# CORE_LA register map
Vendor: Texas Instruments
Peripheral module from a debugger description file (folder omap36xx).
Registers are 32-bit, read-only, reset values left out (the file's numbers can be read two ways) unless marked. A register's access mark holds for its fields unless they carry their own. Offsets are as the file gives them; lines under a group give offsets from that group; [hi:lo] are bit positions; {n}, {i} and the like mark numbered series; 'fields as' and 'values as' point back to an identical list; <NAME> marks a mode.

## CORE_LA
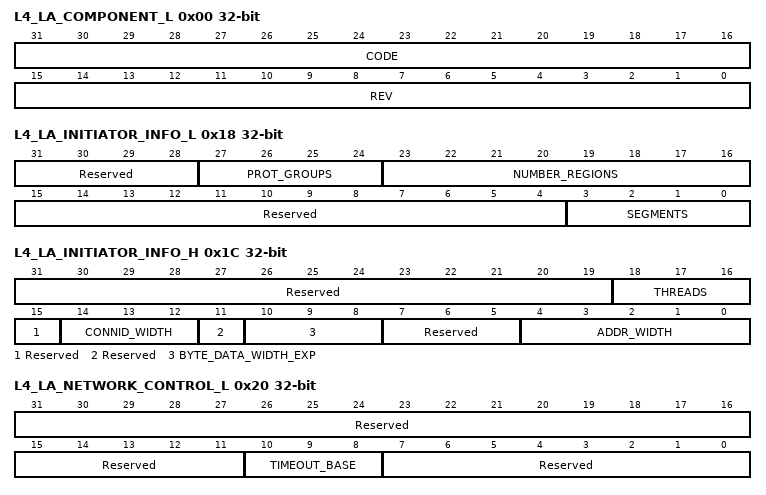
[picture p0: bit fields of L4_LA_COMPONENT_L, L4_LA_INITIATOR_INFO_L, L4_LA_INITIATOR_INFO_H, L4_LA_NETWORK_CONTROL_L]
0x00 L4_LA_COMPONENT_L — Contain a component code and revision, which are used to identify the hardware of the component.
  [31:16] CODE — Interconnect code.
  [15:0] REV — Component revision code.
0x04 L4_LA_COMPONENT_H — Contain a component code and revision, which are used to identify the hardware of the component.
  [31:0] Reserved — Read returns 0
0x10 L4_LA_NETWORK_L — Identify the interconnect
  [31:0] Reserved — Read returns 0
0x14 L4_LA_NETWORK_H — Identify the interconnect
  [31:0] ID — The ID field uniquely identifies this interconnect, and can serve as a chip ID.
0x18 L4_LA_INITIATOR_INFO_L — Contain initiator subsystem information.
  [31:28] Reserved — Read returns 0.
  [27:24] PROT_GROUPS — The number of protection groups. The PROT_GROUPS field contains read-only configuration information for the address mapping and protection structure of the initiator subsystem. If the PROT_GROUPS field is set to 0, there are no protection group registers.
  [23:16] NUMBER_REGIONS — The number of regions. The NUMBER_REGIONS field contains read-only configuration information for the region register of the initiator subsystem.
  [15:4] Reserved — Read returns 0.
  [3:0] SEGMENTS — The number of segments. The SEGMENT fields contains read-only configuration information for the segment register of the initiator subsystem.
0x1C L4_LA_INITIATOR_INFO_H — Contain initiator subsystem information.
  [31:19] Reserved — Read returns 0.
  [18:16] THREADS — The THREADS field specifies the number of initiator threads connected to the interconnect. The field contains read-only configuration information for the initiator subsystem.
  [15] Reserved — Read returns 0.
  [14:12] CONNID_WIDTH — The initiator subsystem connID width. The CONNID_WIDTH field contains read-only configuration information for the initiator subsystem.
  [11] Reserved — Read returns 0.
  [10:8] BYTE_DATA_WIDTH_EXP — This field specifies the initiator subsystem data width. 1:2^1 bytes specifies a 16-bit data width and 2:2^2 bytes specifies a 32-bit data width. The BYTE_DATA_WIDTH_EXP field contains read-only configuration information for the initiator subsystem.
  [7:5] Reserved — Read returns 0.
  [4:0] ADDR_WIDTH — This field specifies the initiator subsystem address width. The ADDR_WIDTH field contains read-only configuration information for the initiator subsystem.
0x20 L4_LA_NETWORK_CONTROL_L access per field — Control interconnect minimum timeout values.
  [31:11] Reserved ro — Read returns 0.
  [10:8] TIMEOUT_BASE rw — The TIMEOUT_BASE field indicates the timeout period (that is, base cycles) for the highest frequency time-base signal sent from the L4 initiator subsystem to all target agents that have timeout enabled. Values for the field are:0 - Timeout disabled1 - L4 interconnect clock cycles divided by 642 - L4 interconnect clock cycles divided by 2563 - L4 interconnect clock cycles divided by 10244 - L4 interconnect clock cycles divided by 4096
  [7:0] Reserved ro — Read returns 0.
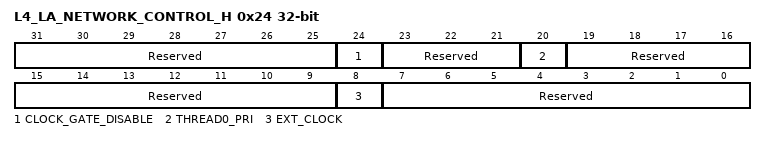
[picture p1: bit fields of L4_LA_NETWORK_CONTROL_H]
0x24 L4_LA_NETWORK_CONTROL_H access per field — Control interconnect global power control
  [31:25] Reserved ro — Read returns 0.
  [24] CLOCK_GATE_DISABLE rw — When set to 1 this field disables all clock gating.
  [23:21] Reserved ro — Read returns 0.
  [20] THREAD0_PRI ro — Sets thread priority. If the field is set to 0, the default, all initiator threads are treated the same. Setting the THREAD0_PRI field to 1 assigns a higher arbitration priority to thread 0 of the first initiator OCP interface. To avoid starvation, arbitration is imposed by the initiator subsystem. When multiple requests from different initiator threads are dispatched to targets simultaneously, the oldest request is dispatched first. If thread 0 is assigned a higher priority, a request on thread 0 always wins arbitration. Assigning thread 0 of the first initiator OCP the highest priority on a request or response can result in the starvation of other threads.
  [19:9] Reserved ro — Read returns 0.
  [8] EXT_CLOCK ro — When set to 1, the ext_clk_off_i signal on the initiator subsystem instructs the entire L4 to shut off.
  [7:0] Reserved ro — Read returns 0.
